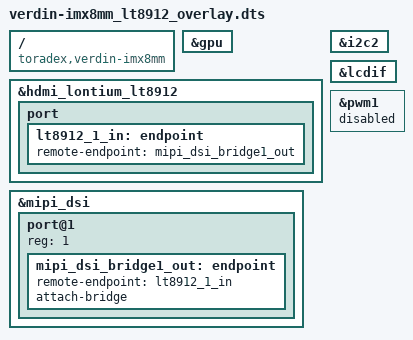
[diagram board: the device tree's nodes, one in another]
// SPDX-License-Identifier: GPL-2.0-or-later OR MIT
/*
 * Copyright 2020-2021 Toradex
 */

// Verdin DSI to HDMI Adapter orderable at Toradex.

/dts-v1/;
/plugin/;

/ {
	compatible = "toradex,verdin-imx8mm";
};

&gpu {
	status = "okay";
};

&hdmi_lontium_lt8912 {
	status = "okay";

	port {
		lt8912_1_in: endpoint {
			remote-endpoint = <&mipi_dsi_bridge1_out>;
		};
	};
};

/* Verdin I2C_2_DSI */
&i2c2 {
	status = "okay";
};

&lcdif {
	status = "okay";
};

&mipi_dsi {
	#address-cells = <1>;
	#size-cells = <0>;
	status = "okay";

	port@1 {
		reg = <1>;

		mipi_dsi_bridge1_out: endpoint {
			remote-endpoint = <&lt8912_1_in>;
			attach-bridge;
		};
	};
};

&pwm1 {
	status = "disabled";
};
